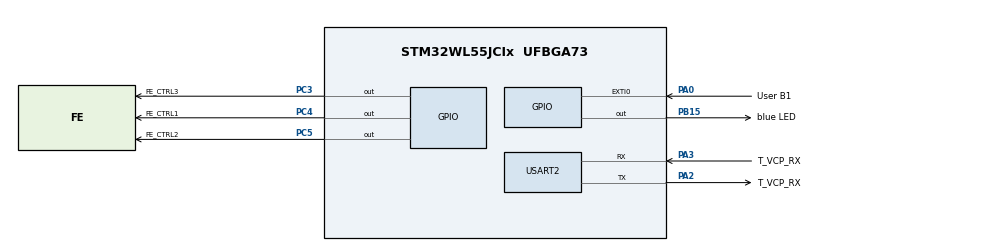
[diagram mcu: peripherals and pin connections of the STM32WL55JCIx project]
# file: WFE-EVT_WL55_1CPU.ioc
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Mcu.Family=STM32WL
Mcu.Name=STM32WL55JCIx
Mcu.Package=UFBGA73
NVIC.PriorityGroup=NVIC_PRIORITYGROUP_4
PA0.GPIO_Label=User B1
PA0.GPIO_ModeDefaultEXTI=GPIO_MODE_EVT_FALLING
PA0.GPIO_PuPd=GPIO_PULLUP
PA0.Signal=GPXTI0
PA2.GPIO_Label=T_VCP_RX
PA2.Mode=Asynchronous
PA2.Signal=USART2_TX
PA3.GPIO_Label=T_VCP_RX
PA3.Mode=Asynchronous
PA3.Signal=USART2_RX
PB15.GPIO_Label=blue LED
PB15.Signal=GPIO_Output
PC14-OSC32_IN.GPIO_Label=RCC_OSC32_IN
PC14-OSC32_IN.Signal=RCC_OSC32_IN
PC15-OSC32_OUT.GPIO_Label=RCC_OSC32_OUT
PC15-OSC32_OUT.Signal=RCC_OSC32_OUT
PC3.GPIO_Label=FE_CTRL3
PC3.GPIO_Speed=GPIO_SPEED_FREQ_VERY_HIGH
PC3.Signal=GPIO_Output
PC4.GPIO_Label=FE_CTRL1
PC4.GPIO_Speed=GPIO_SPEED_FREQ_VERY_HIGH
PC4.Signal=GPIO_Output
PC5.GPIO_Label=FE_CTRL2
PC5.GPIO_Speed=GPIO_SPEED_FREQ_VERY_HIGH
PC5.Signal=GPIO_Output
ProjectManager.HeapSize=0x200
ProjectManager.StackSize=0x400
ProjectManager.TargetToolchain=STM32CubeIDE
RCC.AHBFreq_Value=48000000
RCC.APB1Freq_Value=48000000
RCC.APB1TimFreq_Value=48000000
RCC.APB2Freq_Value=48000000
RCC.APB2TimFreq_Value=48000000
RCC.APB3Freq_Value=48000000
RCC.CortexFreq_Value=48000000
RCC.HCLKFreq_Value=48000000
RCC.HSE_VALUE=32000000
RCC.HSI_VALUE=16000000
RCC.LSE_VALUE=32768
RCC.PLLN=24
RCC.SYSCLKFreq_VALUE=48000000
RCC.SYSCLKSource=RCC_SYSCLKSOURCE_PLLCLK
RCC.VCOOutputFreq_Value=96000000
USART2.VirtualMode-Asynchronous=VM_ASYNC
board=NUCLEO-WL55JC1

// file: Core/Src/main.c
/* USER CODE BEGIN Header */
/**
  ******************************************************************************
  * @file           : main.c
  * @brief          : Main program body
  ******************************************************************************
  * @attention
  *
  * Copyright (c) 2025 STMicroelectronics.
  * All rights reserved.
  *
  * This software is licensed under terms that can be found in the LICENSE file
  * in the root directory of this software component.
  * If no LICENSE file comes with this software, it is provided AS-IS.
  *
  ******************************************************************************
  */
/* USER CODE END Header */
#include "main.h"

/* USER CODE BEGIN Includes */
#include <stdio.h>
/* USER CODE END Includes */

UART_HandleTypeDef huart2;

void SystemClock_Config(void);
static void MX_GPIO_Init(void);
static void MX_USART2_UART_Init(void);

/* USER CODE BEGIN 0 */
int __io_putchar(int ch){
	HAL_UART_Transmit(&huart2, &ch, 1, 1000);
}
/* USER CODE END 0 */

int main(void)
{

  /* MCU Configuration--------------------------------------------------------*/

  /* Reset of all peripherals, Initializes the Flash interface and the Systick. */
  HAL_Init();

  /* Configure the system clock */
  SystemClock_Config();

  /* Initialize all configured peripherals */
  MX_GPIO_Init();
  MX_USART2_UART_Init();

  /* Infinite loop */
  /* USER CODE BEGIN WHILE */
  	  printf("\r\n\r\nTest d'une appli mode veille sur STM32\r\n");
  while (1)
  {
	  printf("Exécution de la boucle While\r\n");
	  printf("Le µCU entre en veille normale via WFE - type event\r\n\r\n");

	  __HAL_RCC_USART2_CLK_SLEEP_DISABLE(); // Clock-gating the USART2 peripheral

	  HAL_SuspendTick();
	  HAL_PWR_EnterSLEEPMode(PWR_MAINREGULATOR_ON, PWR_SLEEPENTRY_WFE);

    /* ####----####
	   * MCU is asleep
	   * ####----####
	   */

	  HAL_ResumeTick(); // MCU wakes up from sleep mode
	  printf("Réveil par pression du Bouton 1\r\n");
    /* USER CODE END WHILE */

  }
}

void SystemClock_Config(void)
{
  RCC_OscInitTypeDef RCC_OscInitStruct = {0};
  RCC_ClkInitTypeDef RCC_ClkInitStruct = {0};

  /** Configure the main internal regulator output voltage
  */
  __HAL_PWR_VOLTAGESCALING_CONFIG(PWR_REGULATOR_VOLTAGE_SCALE1);

  /** Initializes the CPU, AHB and APB buses clocks
  */
  RCC_OscInitStruct.OscillatorType = RCC_OSCILLATORTYPE_MSI;
  RCC_OscInitStruct.MSIState = RCC_MSI_ON;
  RCC_OscInitStruct.MSICalibrationValue = RCC_MSICALIBRATION_DEFAULT;
  RCC_OscInitStruct.MSIClockRange = RCC_MSIRANGE_6;
  RCC_OscInitStruct.PLL.PLLState = RCC_PLL_ON;
  RCC_OscInitStruct.PLL.PLLSource = RCC_PLLSOURCE_MSI;
  RCC_OscInitStruct.PLL.PLLM = RCC_PLLM_DIV1;
  RCC_OscInitStruct.PLL.PLLN = 24;
  RCC_OscInitStruct.PLL.PLLP = RCC_PLLP_DIV2;
  RCC_OscInitStruct.PLL.PLLR = RCC_PLLR_DIV2;
  RCC_OscInitStruct.PLL.PLLQ = RCC_PLLQ_DIV2;
  if (HAL_RCC_OscConfig(&RCC_OscInitStruct) != HAL_OK)
  {
    Error_Handler();
  }

  /** Configure the SYSCLKSource, HCLK, PCLK1 and PCLK2 clocks dividers
  */
  RCC_ClkInitStruct.ClockType = RCC_CLOCKTYPE_HCLK3|RCC_CLOCKTYPE_HCLK
                              |RCC_CLOCKTYPE_SYSCLK|RCC_CLOCKTYPE_PCLK1
                              |RCC_CLOCKTYPE_PCLK2;
  RCC_ClkInitStruct.SYSCLKSource = RCC_SYSCLKSOURCE_PLLCLK;
  RCC_ClkInitStruct.AHBCLKDivider = RCC_SYSCLK_DIV1;
  RCC_ClkInitStruct.APB1CLKDivider = RCC_HCLK_DIV1;
  RCC_ClkInitStruct.APB2CLKDivider = RCC_HCLK_DIV1;
  RCC_ClkInitStruct.AHBCLK3Divider = RCC_SYSCLK_DIV1;

  if (HAL_RCC_ClockConfig(&RCC_ClkInitStruct, FLASH_LATENCY_2) != HAL_OK)
  {
    Error_Handler();
  }
}

static void MX_USART2_UART_Init(void)
{

  huart2.Instance = USART2;
  huart2.Init.BaudRate = 115200;
  huart2.Init.WordLength = UART_WORDLENGTH_8B;
  huart2.Init.StopBits = UART_STOPBITS_1;
  huart2.Init.Parity = UART_PARITY_NONE;
  huart2.Init.Mode = UART_MODE_TX_RX;
  huart2.Init.HwFlowCtl = UART_HWCONTROL_NONE;
  huart2.Init.OverSampling = UART_OVERSAMPLING_16;
  huart2.Init.OneBitSampling = UART_ONE_BIT_SAMPLE_DISABLE;
  huart2.Init.ClockPrescaler = UART_PRESCALER_DIV1;
  huart2.AdvancedInit.AdvFeatureInit = UART_ADVFEATURE_NO_INIT;
  if (HAL_UART_Init(&huart2) != HAL_OK)
  {
    Error_Handler();
  }
  if (HAL_UARTEx_SetTxFifoThreshold(&huart2, UART_TXFIFO_THRESHOLD_1_8) != HAL_OK)
  {
    Error_Handler();
  }
  if (HAL_UARTEx_SetRxFifoThreshold(&huart2, UART_RXFIFO_THRESHOLD_1_8) != HAL_OK)
  {
    Error_Handler();
  }
  if (HAL_UARTEx_DisableFifoMode(&huart2) != HAL_OK)
  {
    Error_Handler();
  }

}

static void MX_GPIO_Init(void)
{
  GPIO_InitTypeDef GPIO_InitStruct = {0};

  /* GPIO Ports Clock Enable */
  __HAL_RCC_GPIOB_CLK_ENABLE();
  __HAL_RCC_GPIOC_CLK_ENABLE();
  __HAL_RCC_GPIOA_CLK_ENABLE();

  /*Configure GPIO pin Output Level */
  HAL_GPIO_WritePin(blue_LED_GPIO_Port, blue_LED_Pin, GPIO_PIN_RESET);

  /*Configure GPIO pin Output Level */
  HAL_GPIO_WritePin(GPIOC, FE_CTRL3_Pin|FE_CTRL2_Pin|FE_CTRL1_Pin, GPIO_PIN_RESET);

  /*Configure GPIO pin : blue_LED_Pin */
  GPIO_InitStruct.Pin = blue_LED_Pin;
  GPIO_InitStruct.Mode = GPIO_MODE_OUTPUT_PP;
  GPIO_InitStruct.Pull = GPIO_NOPULL;
  GPIO_InitStruct.Speed = GPIO_SPEED_FREQ_LOW;
  HAL_GPIO_Init(blue_LED_GPIO_Port, &GPIO_InitStruct);

  /*Configure GPIO pins : FE_CTRL3_Pin FE_CTRL2_Pin FE_CTRL1_Pin */
  GPIO_InitStruct.Pin = FE_CTRL3_Pin|FE_CTRL2_Pin|FE_CTRL1_Pin;
  GPIO_InitStruct.Mode = GPIO_MODE_OUTPUT_PP;
  GPIO_InitStruct.Pull = GPIO_NOPULL;
  GPIO_InitStruct.Speed = GPIO_SPEED_FREQ_VERY_HIGH;
  HAL_GPIO_Init(GPIOC, &GPIO_InitStruct);

  /*Configure GPIO pin : User_B1_Pin */
  GPIO_InitStruct.Pin = User_B1_Pin;
  GPIO_InitStruct.Mode = GPIO_MODE_EVT_FALLING;
  GPIO_InitStruct.Pull = GPIO_PULLUP;
  HAL_GPIO_Init(User_B1_GPIO_Port, &GPIO_InitStruct);

}

void Error_Handler(void)
{
  __disable_irq();
  while (1)
  {
  }
}
